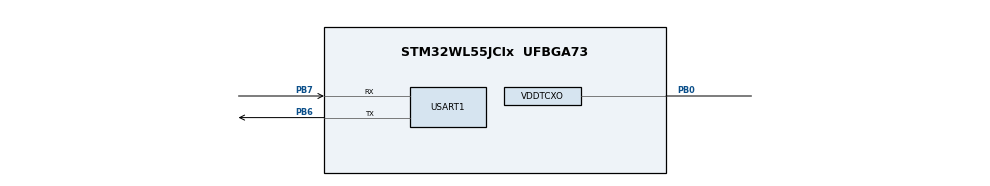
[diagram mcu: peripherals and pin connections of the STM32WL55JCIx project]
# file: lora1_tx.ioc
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Dma.Request0=USART1_RX
Dma.Request1=USART1_TX
Dma.USART1_RX.0.Channel_PRIV_NPRIV=DMA_CHANNEL_NPRIV_DISABLE
Dma.USART1_RX.0.Direction=DMA_PERIPH_TO_MEMORY
Dma.USART1_RX.0.EventEnable=DISABLE
Dma.USART1_RX.0.Instance=DMA1_Channel1
Dma.USART1_RX.0.MemDataAlignment=DMA_MDATAALIGN_BYTE
Dma.USART1_RX.0.MemInc=DMA_MINC_ENABLE
Dma.USART1_RX.0.Mode=DMA_NORMAL
Dma.USART1_RX.0.PeriphDataAlignment=DMA_PDATAALIGN_BYTE
Dma.USART1_RX.0.PeriphInc=DMA_PINC_DISABLE
Dma.USART1_RX.0.Polarity=HAL_DMAMUX_REQ_GEN_RISING
Dma.USART1_RX.0.Priority=DMA_PRIORITY_LOW
Dma.USART1_RX.0.RequestNumber=1
Dma.USART1_RX.0.SignalID=NONE
Dma.USART1_RX.0.SyncEnable=DISABLE
Dma.USART1_RX.0.SyncPolarity=HAL_DMAMUX_SYNC_NO_EVENT
Dma.USART1_RX.0.SyncRequestNumber=1
Dma.USART1_RX.0.SyncSignalID=NONE
Dma.USART1_TX.1.Channel_PRIV_NPRIV=DMA_CHANNEL_NPRIV_DISABLE
Dma.USART1_TX.1.Direction=DMA_MEMORY_TO_PERIPH
Dma.USART1_TX.1.EventEnable=DISABLE
Dma.USART1_TX.1.Instance=DMA1_Channel2
Dma.USART1_TX.1.MemDataAlignment=DMA_MDATAALIGN_BYTE
Dma.USART1_TX.1.MemInc=DMA_MINC_ENABLE
Dma.USART1_TX.1.Mode=DMA_NORMAL
Dma.USART1_TX.1.PeriphDataAlignment=DMA_PDATAALIGN_BYTE
Dma.USART1_TX.1.PeriphInc=DMA_PINC_DISABLE
Dma.USART1_TX.1.Polarity=HAL_DMAMUX_REQ_GEN_RISING
Dma.USART1_TX.1.Priority=DMA_PRIORITY_LOW
Dma.USART1_TX.1.RequestNumber=1
Dma.USART1_TX.1.SignalID=NONE
Dma.USART1_TX.1.SyncEnable=DISABLE
Dma.USART1_TX.1.SyncPolarity=HAL_DMAMUX_SYNC_NO_EVENT
Dma.USART1_TX.1.SyncRequestNumber=1
Dma.USART1_TX.1.SyncSignalID=NONE
Mcu.Family=STM32WL
Mcu.Name=STM32WL55JCIx
Mcu.Package=UFBGA73
NVIC.DMA1_Channel1_IRQn=true\:0\:0\:false\:false\:true\:false\:true
NVIC.DMA1_Channel2_IRQn=true\:0\:0\:false\:false\:true\:false\:true
NVIC.PriorityGroup=NVIC_PRIORITYGROUP_4
NVIC.SUBGHZ_Radio_IRQn=true\:0\:0\:false\:false\:true\:true\:true
NVIC.USART1_IRQn=true\:0\:0\:false\:false\:true\:true\:true
OSC_IN.Mode=HSE-TCXO
OSC_IN.Signal=RCC_OSC_IN
PB0-VDD_TCXO.Mode=HSE-TCXO
PB0-VDD_TCXO.Signal=VDDTCXO
PB6.Mode=Asynchronous
PB6.Signal=USART1_TX
PB7.Mode=Asynchronous
PB7.Signal=USART1_RX
PC14-OSC32_IN.Mode=LSE-External-Oscillator
PC14-OSC32_IN.Signal=RCC_OSC32_IN
PC15-OSC32_OUT.Mode=LSE-External-Oscillator
PC15-OSC32_OUT.Signal=RCC_OSC32_OUT
ProjectManager.HeapSize=0x200
ProjectManager.StackSize=0x400
ProjectManager.TargetToolchain=STM32CubeIDE
RCC.AHBFreq_Value=48000000
RCC.APB1Freq_Value=48000000
RCC.APB1TimFreq_Value=48000000
RCC.APB2Freq_Value=48000000
RCC.APB2TimFreq_Value=48000000
RCC.APB3Freq_Value=48000000
RCC.CortexFreq_Value=48000000
RCC.HCLKFreq_Value=48000000
RCC.HSE_VALUE=8000000
RCC.HSI_VALUE=16000000
RCC.LSE_VALUE=32768
RCC.MSIClockRange=RCC_MSIRANGE_11
RCC.SYSCLKFreq_VALUE=48000000
RCC.VCOOutputFreq_Value=384000000
SUBGHZ.BaudratePrescaler=SUBGHZSPI_BAUDRATEPRESCALER_4
SUBGHZ_PHY.RF_WAKEUP_TIME=10
USART1.VirtualMode-Asynchronous=VM_ASYNC
VP_ADV_TRACE_VS_ADV_TRACE.Mode=ADV_TRACE_Enabled
VP_MISC_VS_MISC.Mode=MISC_Enabled
VP_SEQUENCER_M4_VS_SEQUENCER.Mode=SEQUENCER_Enabled
VP_SUBGHZ_PHY_VS_SubGhzPhy.Mode=SubGhzPhy_Enabled
VP_SUBGHZ_VS_SUBGHZ.Mode=SUBGHZ_Activate
VP_TIMER_VS_TIMER.Mode=TIMER_Enabled
VP_TINY_LPM_VS_TINY_LPM.Mode=TINY_LPM_Enabled
board=custom

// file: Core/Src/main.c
/* USER CODE BEGIN Header */
/**
  ******************************************************************************
  * @file           : main.c
  * @brief          : Main program body
  ******************************************************************************
  * @attention
  *
  * <h2><center>&copy; Copyright (c) 2023 STMicroelectronics.
  * All rights reserved.</center></h2>
  *
  * This software component is licensed by ST under Ultimate Liberty license
  * SLA0044, the "License"; You may not use this file except in compliance with
  * the License. You may obtain a copy of the License at:
  *                             www.st.com/SLA0044
  *
  ******************************************************************************
  */
/* USER CODE END Header */
#include "main.h"
#include "dma.h"
#include "app_subghz_phy.h"
#include "usart.h"
#include "gpio.h"

/* USER CODE BEGIN Includes */
#include"radio_driver.h"
#include "stdio.h"
#include "string.h"
#include<stdarg.h>
/* USER CODE END Includes */

/* USER CODE BEGIN PTD */
#define PAYLOAD_LENGTH          (5)
#define CMD_LEN					(5) // Receiveing GS Command
#define CW_TX_LEN				(5)

//#define CRC_TYPE                (0x01) // crc disabled
//#define WHITENING               (0x00) // whitening disabled

#define FREQ_401_MHZ          	(401375000)	//  (401375000) //dlink
#define FREQ_402_MHZ		  	(402375000)	//	(402375000) //UPLINK

#define PA_DUTY_CYCLE           (0x04)
#define HP_MAX                  (0x07)
#define PA_SEL                  (0x00)

#define POWER                   (0x15)
#define RAMP_TIME               (0x05)
/* USER CODE END PTD */

/* USER CODE BEGIN PM */
static __IO uint8_t TX_Flag = 0;
uint8_t rx_ack[2] = { 0xac, 0xad };
/* USER CODE END PM */

/* USER CODE BEGIN PV */
uint8_t tx_buf[PAYLOAD_LENGTH];
uint8_t rx_buf[CMD_LEN] = { 0 };
uint8_t p_len = CMD_LEN;
uint8_t RX_FLAG=0;
/* USER CODE END PV */

void SystemClock_Config(void);
/* USER CODE BEGIN PFP */
void DioIrqHndlr(RadioIrqMasks_t radioIrq) {
	switch (radioIrq) {
	case IRQ_RADIO_NONE:

		break;
	case IRQ_RX_DONE:

		myprintf("DATA RECEIVED: \n");
		SUBGRF_GetPayload(rx_buf, &p_len, PAYLOAD_LENGTH);
		myprintf("%s",rx_buf);
		HAL_UART_Transmit_IT(&huart1, rx_buf, CMD_LEN);

		SUBGRF_SetSwitch(1, RFSWITCH_RX);
		SUBGRF_SetRxBoosted(0xFFFFFF);
//		rx_buf[33] = SUBGRF_GetRssiInst();
//		RX_FLAG =1;
		break;

	case IRQ_TX_DONE:

		memset((char*) tx_buf, '\0', PAYLOAD_LENGTH);

		//            myprintf("%s",tx_buf);
		SUBGRF_SetSwitch(1, RFSWITCH_RX); /*Set RF switch*/
		SUBGRF_SetRxBoosted(0xFFFFFF);
		//            myprintf("\n\rGoing RX_Mode\n\r");
		SUBGRF_SetRfFrequency(FREQ_402_MHZ);
		memset(rx_buf, '\0', CMD_LEN); //Clear RX_BUFFER

		break;
	case IRQ_PREAMBLE_DETECTED:

		break;
	case IRQ_SYNCWORD_VALID:

		break;
	case IRQ_HEADER_VALID:

		break;
	case IRQ_HEADER_ERROR:

		break;
	case IRQ_CRC_ERROR:

		break;
	case IRQ_CAD_CLEAR:

		break;
	case IRQ_CAD_DETECTED:

		break;
	case IRQ_RX_TX_TIMEOUT:

		break;
	}
}

int buffersize(char *buff) {
	int i = 0;

	while (*buff++ != '\0')
		i++;
	return i;
}
void myprintf(const char *fmt, ...) {
	static char temp[255];
	va_list args;
	va_start(args, fmt);
	vsnprintf(temp, sizeof(temp), fmt, args);
	va_end(args);
	int len = buffersize(temp);
	HAL_UART_Transmit(&huart1, (uint8_t*)temp, len, 5000);

}
/* USER CODE END PFP */

int main(void)
{

  /* MCU Configuration--------------------------------------------------------*/

  /* Reset of all peripherals, Initializes the Flash interface and the Systick. */
  HAL_Init();

  /* Configure the system clock */
  SystemClock_Config();

  /* Initialize all configured peripherals */
  MX_GPIO_Init();
  MX_DMA_Init();
  MX_USART1_UART_Init();
  MX_SubGHz_Phy_Init();
  /* USER CODE BEGIN 2 */

  PacketParams_t pkt_params;
  	pkt_params.PacketType = PACKET_TYPE_LORA;
  	pkt_params.Params.LoRa.PayloadLength = PAYLOAD_LENGTH;
  	pkt_params.Params.LoRa.PreambleLength = 8;
  	pkt_params.Params.LoRa.HeaderType = LORA_PACKET_IMPLICIT;
  	pkt_params.Params.LoRa.CrcMode = LORA_CRC_ON;
  	pkt_params.Params.LoRa.InvertIQ = LORA_IQ_NORMAL;

  ModulationParams_t mod_params;
  	mod_params.PacketType = PACKET_TYPE_LORA;
  	mod_params.Params.LoRa.Bandwidth = LORA_BW_031;
  	mod_params.Params.LoRa.SpreadingFactor = LORA_SF10;
  	mod_params.Params.LoRa.CodingRate = LORA_CR_4_8;
  	mod_params.Params.LoRa.LowDatarateOptimize = 1;

	SUBGRF_Init(DioIrqHndlr);
	SUBGRF_SetBufferBaseAddress(0x00, 0x00);
	SUBGRF_SetPayload(tx_buf, CMD_LEN);
	SUBGRF_SetPacketParams(&pkt_params);
	SUBGRF_SetSyncWord(( uint8_t[] ) { 0xC1, 0x94, 0xC1, 0x00, 0x00, 0x00, 0x00,
					0x00 });
	SUBGRF_SetWhiteningSeed(0x01FF);
	SUBGRF_SetRfFrequency(FREQ_402_MHZ);
	SUBGRF_SetPaConfig(PA_DUTY_CYCLE, HP_MAX, PA_SEL, 0x01);
	SUBGRF_SetTxParams(RFO_HP, POWER, RAMP_TIME);
	SUBGRF_SetModulationParams(&mod_params);
	SUBGRF_SetDioIrqParams(
			IRQ_TX_DONE | IRQ_PREAMBLE_DETECTED | IRQ_RX_DONE
					| IRQ_RX_TX_TIMEOUT | IRQ_SYNCWORD_VALID,
			IRQ_TX_DONE | IRQ_PREAMBLE_DETECTED | IRQ_RX_DONE
					| IRQ_RX_TX_TIMEOUT | IRQ_SYNCWORD_VALID, IRQ_RADIO_NONE,
			IRQ_RADIO_NONE);

	myprintf("########## MUNAL SATELLITE COM: BEGIN ##########\r\n");

	myprintf("########## COMMUNICATION PARAMETERS:  ##########\r\n");
	myprintf("Modulation  LoRa PACKET	./\r\n");
	myprintf("FREQUENCY MODS: UPLINK FREQ: %lu\r\n DOWNLINK FREQ: %lu\r\n",
	FREQ_402_MHZ, FREQ_401_MHZ);
	myprintf(
			"POWER CONFIG: PA_DUTY_CYCLE : %x, HP_MAX: %x,PA_SEL : %x \n\r POWER TX: %u dBm\n\r",
			PA_DUTY_CYCLE, HP_MAX, PA_SEL, POWER);
	myprintf("RECEVING BANDWIDTH: 	%d\n\r", mod_params.Params.LoRa.Bandwidth);
	myprintf("Packet Type 			%d\n\r  ", pkt_params.PacketType);
	myprintf("PayloadLength 			%d\n\r  ", pkt_params.Params.LoRa.PayloadLength);
	myprintf("PreambleLength 		%d\n\r", pkt_params.Params.LoRa.PreambleLength);
	myprintf("PreambleMinDetect		%d\n\r",
			pkt_params.Params.Gfsk.PreambleMinDetect);
	myprintf("HeaderType 			%d\n\r", pkt_params.Params.LoRa.HeaderType);
	myprintf("__________________________________________________\r\n");
	myprintf("________________Waiting OBC DATA____________\r\n");

	SUBGRF_SetSwitch(RFO_HP, RFSWITCH_RX); /*Set RF switch*/
	SUBGRF_SetRxBoosted(0xFFFFFF);
	HAL_UART_Receive_IT(&huart1,tx_buf,sizeof(tx_buf));
  /* USER CODE END 2 */

  /* Infinite loop */
  while (1)
  {
    MX_SubGHz_Phy_Process();

  }
}

void SystemClock_Config(void)
{
  RCC_OscInitTypeDef RCC_OscInitStruct = {0};
  RCC_ClkInitTypeDef RCC_ClkInitStruct = {0};

  /** Configure LSE Drive Capability
  */
  HAL_PWR_EnableBkUpAccess();
  __HAL_RCC_LSEDRIVE_CONFIG(RCC_LSEDRIVE_LOW);
  /** Configure the main internal regulator output voltage
  */
  __HAL_PWR_VOLTAGESCALING_CONFIG(PWR_REGULATOR_VOLTAGE_SCALE1);
  /** Initializes the CPU, AHB and APB busses clocks
  */
  RCC_OscInitStruct.OscillatorType = RCC_OSCILLATORTYPE_LSE|RCC_OSCILLATORTYPE_MSI;
  RCC_OscInitStruct.LSEState = RCC_LSE_ON;
  RCC_OscInitStruct.MSIState = RCC_MSI_ON;
  RCC_OscInitStruct.MSICalibrationValue = RCC_MSICALIBRATION_DEFAULT;
  RCC_OscInitStruct.MSIClockRange = RCC_MSIRANGE_11;
  RCC_OscInitStruct.PLL.PLLState = RCC_PLL_NONE;
  if (HAL_RCC_OscConfig(&RCC_OscInitStruct) != HAL_OK)
  {
    Error_Handler();
  }
  /** Configure the SYSCLKSource, HCLK, PCLK1 and PCLK2 clocks dividers
  */
  RCC_ClkInitStruct.ClockType = RCC_CLOCKTYPE_HCLK3|RCC_CLOCKTYPE_HCLK
                              |RCC_CLOCKTYPE_SYSCLK|RCC_CLOCKTYPE_PCLK1
                              |RCC_CLOCKTYPE_PCLK2;
  RCC_ClkInitStruct.SYSCLKSource = RCC_SYSCLKSOURCE_MSI;
  RCC_ClkInitStruct.AHBCLKDivider = RCC_SYSCLK_DIV1;
  RCC_ClkInitStruct.APB1CLKDivider = RCC_HCLK_DIV1;
  RCC_ClkInitStruct.APB2CLKDivider = RCC_HCLK_DIV1;
  RCC_ClkInitStruct.AHBCLK3Divider = RCC_SYSCLK_DIV1;

  if (HAL_RCC_ClockConfig(&RCC_ClkInitStruct, FLASH_LATENCY_2) != HAL_OK)
  {
    Error_Handler();
  }
}

/* USER CODE BEGIN 4 */

void HAL_UART_RxCpltCallback(UART_HandleTypeDef *huart){
	HAL_UART_Transmit_IT(&huart1,"received",8);
	SUBGRF_SetSwitch(1, RFSWITCH_TX);
	SUBGRF_SendPayload("lorada", 6, 0);
	SUBGRF_SendPayload(tx_buf, sizeof(tx_buf), 0);
	SUBGRF_SetSwitch(1, RFSWITCH_RX);
	HAL_UART_Receive_IT(&huart1,tx_buf,sizeof(tx_buf));
}

/* USER CODE END 4 */

void Error_Handler(void)
{
  __disable_irq();
  while (1)
  {
  }
}

/************************ (C) COPYRIGHT STMicroelectronics *****END OF FILE****/
